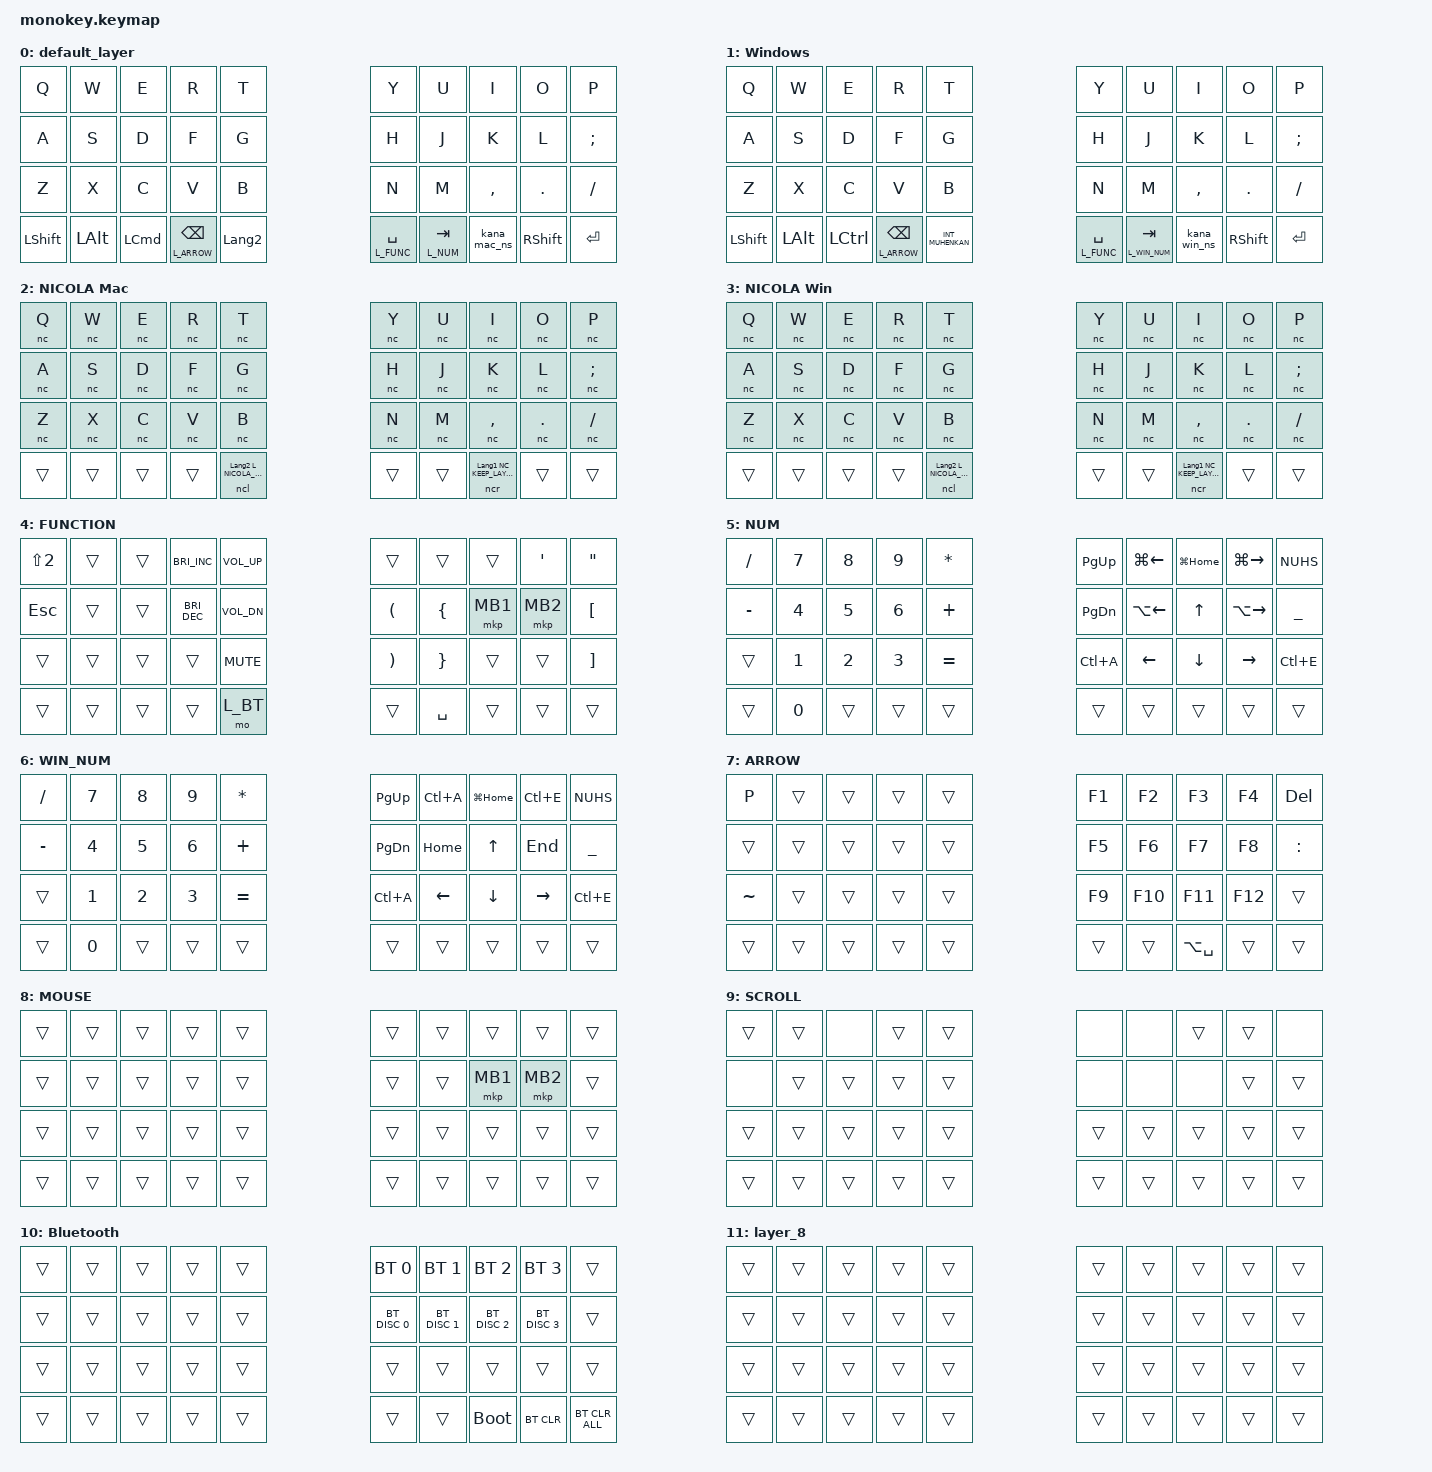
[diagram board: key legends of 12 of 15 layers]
#include <behaviors.dtsi>
#include <behaviors/nicola.dtsi>
#include <dt-bindings/zmk/bt.h>
#include <dt-bindings/zmk/keys.h>
#include <dt-bindings/zmk/pointing.h>

// レイヤー番号。NICOLA（親指シフト）レイヤーを基本レイヤーの直上に置き、FUNCTION 以降の
// ユーティリティレイヤーはその上に重なるようにする（NICOLA 中でも Space/Tab/Backspace の
// 長押しレイヤーが従来どおり使える）。番号を変えるときは monokey_R.overlay の
// zip_temp_layer / scroll-layers と monokey_R.conf の LAYER_n_COLOR も合わせる。
#define L_MAC        0
#define L_WIN        1
#define L_NICOLA_MAC 2
#define L_NICOLA_WIN 3
#define L_FUNC       4
#define L_NUM        5
#define L_WIN_NUM    6
#define L_ARROW      7
#define L_MOUSE      8
#define L_SCROLL     9
#define L_BT         10
#define L_SPARE_A    11
#define L_SPARE_B    12
#define L_SPARE_C    13
#define L_SPARE_D    14

// 文字キー同士の combo を NICOLA レイヤーでは無効にする（かなの高速ロールオーバーを
// combo が食わないようにする）。combo の layers に指定する。
#define NON_NICOLA_LAYERS L_MAC L_WIN L_FUNC L_NUM L_WIN_NUM L_ARROW L_MOUSE L_SCROLL L_BT L_SPARE_A L_SPARE_B L_SPARE_C L_SPARE_D
// Ctrl の combo は NICOLA レイヤーでも使う（Mac には Ctrl の物理キーがなく、入力中の
// Ctrl+K などに必要）。require-prior-idle-ms で直前の打鍵から間が空いたときだけ発火させ、
// かなの高速ロールオーバーを combo が食わないようにする。
#define ALL_LAYERS NON_NICOLA_LAYERS L_NICOLA_MAC L_NICOLA_WIN
#define CTRL_COMBO_IDLE_MS 150

// 親指シフト（NICOLA）の判定設定。Lacaille の使用感に合わせた初期値。
// - 判定方式: ms 方式（文字キーと親指キーの押下間隔が timeout-ms 以内なら同時打鍵）。
//   親指を先に押して遅れて文字を打った場合は窓に関係なくシフトがかかる。
// - 連続シフト: オン（親指を押し続けている間、後続の文字にもシフトがかかる）。
//   ただし親指がすでに文字をシフト済みのとき、次の文字キー押下から shift-release-ms 以内に
//   その親指が離されたら「離し遅れ」とみなして次の文字はシフトしない（「ょう」が「ょゔ」になる対策）。
// - 未確定ガード: かなを送出してから Enter/Esc を見るまでは、左親指単独タップの英数を抑止。
//   同じタップを guard-repeat-ms 以内に繰り返すと通す。
//   送ったかなの数を数え、Backspace/Delete で 1 ずつ減らして 0 になれば抑止を解除する
//   （変換中の最初の Backspace は取消扱い、修飾キー付きと guard-bs-hold-ms 以上の長押しは全消し扱い）。
//   最後のキー押下から guard-timeout-ms 無操作なら未確定文字は消えたとみなして抑止しない
//   （マウスでの確定やアプリ切替など、キーボードから見えない確定への備え）。
&nc {
    timeout-ms = <70>;
    continuous-shift = <1>;
    shift-release-ms = <50>;
    left-thumb = <LANGUAGE_2>;
    right-thumb = <LANGUAGE_1>;
    pending-guard = <1>;
    guard-repeat-ms = <1000>;
    guard-timeout-ms = <3000>;
    guard-bs-hold-ms = <500>;
};

&mt {
    flavor = "balanced";
    quick-tap-ms = <300>;
};

&lt { quick-tap-ms = <300>; };

/ {
    combos {
        compatible = "zmk,combos";

        scroll {
            layers = <NON_NICOLA_LAYERS>;
            bindings = <&mo L_SCROLL>;
            key-positions = <17 18>;
        };

        mb3 {
            layers = <NON_NICOLA_LAYERS>;
            bindings = <&mkp MB3>;
            key-positions = <19 18>;
        };

        right_ctrl {
            layers = <ALL_LAYERS>;
            require-prior-idle-ms = <CTRL_COMBO_IDLE_MS>;
            bindings = <&kp RCTRL>;
            key-positions = <28 29>;
        };

        left_ctrl {
            layers = <ALL_LAYERS>;
            require-prior-idle-ms = <CTRL_COMBO_IDLE_MS>;
            bindings = <&kp LCTRL>;
            key-positions = <20 21>;
        };

        changewin {
            layers = <NON_NICOLA_LAYERS>;
            timeout-ms = <50>;
            bindings = <&os_switch_hold L_WIN 0>;
            key-positions = <6 8>;
        };

        tomac {
            layers = <NON_NICOLA_LAYERS>;
            timeout-ms = <50>;
            bindings = <&os_switch_hold L_MAC 0>;
            key-positions = <7 8>;
        };

        lang1 {
            // NICOLA レイヤーでは位置37が右親指シフトなので除外する。
            // Shift が押されていても剥がして送る（Shift+かな は macOS でカタカナ固定）。
            layers = <NON_NICOLA_LAYERS>;
            bindings = <&lang1_ns>;
            key-positions = <36 37>;
        };

        lang2 {
            // LANG2 is IME Off on Windows; keep it out of thumb-shift chords.
            layers = <L_MAC>;
            bindings = <&kp LANGUAGE_2>;
            key-positions = <35 34>;
        };

        win {
            layers = <NON_NICOLA_LAYERS>;
            bindings = <&kp LEFT_GUI>;
            key-positions = <24 23>;
        };
    };

    behaviors {
        // かな (LANG1) を送るキーは、押されている Shift を剥がす。
        // macOS では Shift+かな がカタカナ固定モードへの切替なので、Shift の離し遅れや
        // 隣の右 Shift (位置38) との同時押しで偶発的にカタカナになるのを防ぐ。
        // mod-morph は両方の binding を同じにし、mods に Shift を指定すると Shift をマスクして送る。
        kana_mac_ns: kana_mac_ns {
            compatible = "zmk,behavior-mod-morph";
            #binding-cells = <0>;
            bindings = <&kana_mac>, <&kana_mac>;
            mods = <(MOD_LSFT|MOD_RSFT)>;
        };

        kana_win_ns: kana_win_ns {
            compatible = "zmk,behavior-mod-morph";
            #binding-cells = <0>;
            bindings = <&kana_win>, <&kana_win>;
            mods = <(MOD_LSFT|MOD_RSFT)>;
        };

        lang1_ns: lang1_ns {
            compatible = "zmk,behavior-mod-morph";
            #binding-cells = <0>;
            bindings = <&kp LANGUAGE_1>, <&kp LANGUAGE_1>;
            mods = <(MOD_LSFT|MOD_RSFT)>;
        };

        // Cancel on the first combo-key release; other keys must not force a hold.
        // A short combo is consumed without emitting text or changing layers.
        os_switch_hold: os_switch_hold {
            compatible = "zmk,behavior-hold-tap";
            #binding-cells = <2>;
            flavor = "tap-preferred";
            tapping-term-ms = <500>;
            quick-tap-ms = <0>;
            bindings = <&to>, <&none>;
        };

        right_click: right_click_behavior {
            compatible = "zmk,behavior-mouse-key";
            label = "RIGHT_CLICK";
            #binding-cells = <0>;

            // 右クリックは通常 MB2 に対応（ZMKの標準定義）

            bindings = <&mkp MB2>;
        };
    };

    macros {
        lang2_4: lang2_4 {
            compatible = "zmk,behavior-macro";
            #binding-cells = <0>;
            wait-ms = <30>;
            tap-ms = <30>;
            bindings = <&kp LANGUAGE_2 &kp NUMBER_4>;
        };

        lang2_5: lang2_5 {
            compatible = "zmk,behavior-macro";
            #binding-cells = <0>;
            wait-ms = <30>;
            tap-ms = <30>;
            bindings =
                <&macro_wait_time 100>,
                <&macro_press>,
                <&kp LANG2>,
                <&macro_tap>,
                <&kp N5>,
                <&macro_release>,
                <&kp LANG2>;
        };

        // かなキー（位置37）: IME をかなにしてから NICOLA レイヤーへ入る。
        // 戻るときは NICOLA レイヤー内の左親指（英数）単独タップが LANG2 を送ってレイヤーを抜ける。
        kana_mac: kana_mac {
            compatible = "zmk,behavior-macro";
            #binding-cells = <0>;
            wait-ms = <10>;
            tap-ms = <10>;
            bindings = <&kp LANGUAGE_1 &tog L_NICOLA_MAC>;
        };

        kana_win: kana_win {
            compatible = "zmk,behavior-macro";
            #binding-cells = <0>;
            wait-ms = <10>;
            tap-ms = <10>;
            bindings = <&kp LANGUAGE_1 &tog L_NICOLA_WIN>;
        };
    };

    keymap {
        compatible = "zmk,keymap";

        default_layer {
            bindings = <
&kp Q           &kp W         &kp E             &kp R                  &kp T                                               &kp Y           &kp U  &kp I      &kp O            &kp P
&kp A           &kp S         &kp D             &kp F                  &kp G                                               &kp H           &kp J  &kp K      &kp L            &kp SEMICOLON
&kp Z           &kp X         &kp C             &kp V                  &kp B                                               &kp N           &kp M  &kp COMMA  &kp PERIOD       &kp SLASH
&kp LEFT_SHIFT  &kp LEFT_ALT  &kp LEFT_COMMAND  &lt L_ARROW BACKSPACE  &kp LANGUAGE_2  &lt L_FUNC SPACE  &lt L_NUM TAB     &kana_mac_ns                      &kp RIGHT_SHIFT  &kp RET
            >;

            sensor-bindings = <&inc_dec_kp PG_UP PAGE_DOWN>;
        };

        Windows {
            bindings = <
&kp Q      &kp W         &kp E             &kp R                  &kp T                                                     &kp Y           &kp U  &kp I      &kp O       &kp P
&kp A      &kp S         &kp D             &kp F                  &kp G                                                     &kp H           &kp J  &kp K      &kp L       &kp SEMICOLON
&kp Z      &kp X         &kp C             &kp V                  &kp B                                                     &kp N           &kp M  &kp COMMA  &kp PERIOD  &kp SLASH
&kp LSHFT  &kp LEFT_ALT  &kp LEFT_CONTROL  &lt L_ARROW BACKSPACE  &kp INT_MUHENKAN  &lt L_FUNC SPACE  &lt L_WIN_NUM TAB     &kana_win_ns                      &kp RSHIFT  &kp RET
            >;

            sensor-bindings = <&inc_dec_kp PG_UP PAGE_DOWN>;
        };

        // 親指シフト（NICOLA）。文字キーは &nc、親指キーは &ncl / &ncr。
        // 左親指（位置34）単独タップ = 英数(LANG2) を送ってこのレイヤーを抜ける。
        // 右親指（位置37）単独タップ = かな(LANG1) を送る（レイヤーは維持）。
        // それ以外のキーは &trans で下のレイヤー（Space/Tab/Backspace の長押しなど）に落とす。
        nicola_mac {
            display-name = "NICOLA Mac";
            bindings = <
&nc Q   &nc W   &nc E   &nc R   &nc T                                                   &nc Y   &nc U   &nc I      &nc O    &nc P
&nc A   &nc S   &nc D   &nc F   &nc G                                                   &nc H   &nc J   &nc K      &nc L    &nc SEMI
&nc Z   &nc X   &nc C   &nc V   &nc B                                                   &nc N   &nc M   &nc COMMA  &nc DOT  &nc SLASH
&trans  &trans  &trans  &trans  &ncl LANGUAGE_2 L_NICOLA_MAC  &trans  &trans            &ncr LANGUAGE_1 NC_KEEP_LAYER       &trans   &trans
            >;
        };

        nicola_win {
            display-name = "NICOLA Win";
            bindings = <
&nc Q   &nc W   &nc E   &nc R   &nc T                                                   &nc Y   &nc U   &nc I      &nc O    &nc P
&nc A   &nc S   &nc D   &nc F   &nc G                                                   &nc H   &nc J   &nc K      &nc L    &nc SEMI
&nc Z   &nc X   &nc C   &nc V   &nc B                                                   &nc N   &nc M   &nc COMMA  &nc DOT  &nc SLASH
&trans  &trans  &trans  &trans  &ncl LANGUAGE_2 L_NICOLA_WIN  &trans  &trans            &ncr LANGUAGE_1 NC_KEEP_LAYER       &trans   &trans
            >;
        };

        FUNCTION {
            bindings = <
&kp LS(NUMBER_2)  &trans  &trans  &kp C_BRI_INC  &kp C_VOL_UP                        &trans                 &trans           &trans    &kp SINGLE_QUOTE  &kp DOUBLE_QUOTES
&kp ESC           &trans  &trans  &kp C_BRI_DEC  &kp C_VOL_DN                        &kp LEFT_PARENTHESIS   &kp LEFT_BRACE   &mkp MB1  &mkp MB2          &kp LEFT_BRACKET
&trans            &trans  &trans  &trans         &kp C_MUTE                          &kp RIGHT_PARENTHESIS  &kp RIGHT_BRACE  &trans    &trans            &kp RIGHT_BRACKET
&trans            &trans  &trans  &trans         &mo L_BT      &trans  &kp SPACE     &trans                                            &trans            &trans
            >;
        };

        NUM {
            bindings = <
&kp SLASH  &kp NUMBER_7  &kp NUMBER_8  &kp NUMBER_9  &kp STAR                   &kp PAGE_UP    &kp LG(LEFT)    &kp LG(HOME)    &kp LG(RIGHT)    &kp NUHS
&kp MINUS  &kp NUMBER_4  &kp NUMBER_5  &kp NUMBER_6  &kp PLUS                   &kp PAGE_DOWN  &kp LA(LEFT)    &kp UP_ARROW    &kp LA(RIGHT)    &kp UNDERSCORE
&trans     &kp NUMBER_1  &kp NUMBER_2  &kp NUMBER_3  &kp EQUAL                  &kp LC(A)      &kp LEFT_ARROW  &kp DOWN_ARROW  &kp RIGHT_ARROW  &kp LC(E)
&trans     &kp NUMBER_0  &trans        &trans        &trans     &trans  &trans  &trans                                         &trans           &trans
            >;
        };

        WIN_NUM {
            bindings = <
&kp SLASH  &kp NUMBER_7  &kp NUMBER_8  &kp NUMBER_9  &kp STAR                   &kp PAGE_UP    &kp LC(A)       &kp LG(HOME)    &kp LC(E)        &kp NUHS
&kp MINUS  &kp NUMBER_4  &kp NUMBER_5  &kp NUMBER_6  &kp PLUS                   &kp PAGE_DOWN  &kp HOME        &kp UP_ARROW    &kp END          &kp UNDERSCORE
&trans     &kp NUMBER_1  &kp NUMBER_2  &kp NUMBER_3  &kp EQUAL                  &kp LC(A)      &kp LEFT_ARROW  &kp DOWN_ARROW  &kp RIGHT_ARROW  &kp LC(E)
&trans     &kp NUMBER_0  &trans        &trans        &trans     &trans  &trans  &trans                                         &trans           &trans
            >;
        };

        ARROW {
            bindings = <
&kp P      &trans  &trans  &trans  &trans                  &kp F1         &kp F2   &kp F3   &kp F4   &kp DELETE
&trans     &trans  &trans  &trans  &trans                  &kp F5         &kp F6   &kp F7   &kp F8   &kp COLON
&kp TILDE  &trans  &trans  &trans  &trans                  &kp F9         &kp F10  &kp F11  &kp F12  &trans
&trans     &trans  &trans  &trans  &trans  &trans  &trans  &kp LA(SPACE)                    &trans   &trans
            >;

            sensor-bindings = <&inc_dec_kp LC(PAGE_UP) LC(PAGE_DOWN)>;
        };

        MOUSE {
            bindings = <
&trans  &trans  &trans  &trans  &trans                  &trans  &trans  &trans    &trans    &trans
&trans  &trans  &trans  &trans  &trans                  &trans  &trans  &mkp MB1  &mkp MB2  &trans
&trans  &trans  &trans  &trans  &trans                  &trans  &trans  &trans    &trans    &trans
&trans  &trans  &trans  &trans  &trans  &trans  &trans  &trans                    &trans    &trans
            >;
        };

        SCROLL {
            bindings = <
&trans  &trans  &none   &trans  &trans                  &none   &none   &trans  &trans  &none
&none   &trans  &trans  &trans  &trans                  &none   &none   &none   &trans  &trans
&trans  &trans  &trans  &trans  &trans                  &trans  &trans  &trans  &trans  &trans
&trans  &trans  &trans  &trans  &trans  &trans  &trans  &trans                  &trans  &trans
            >;
        };

        Bluetooth {
            bindings = <
&trans  &trans  &trans  &trans  &trans                  &bt BT_SEL 0   &bt BT_SEL 1   &bt BT_SEL 2   &bt BT_SEL 3   &trans
&trans  &trans  &trans  &trans  &trans                  &bt BT_DISC 0  &bt BT_DISC 1  &bt BT_DISC 2  &bt BT_DISC 3  &trans
&trans  &trans  &trans  &trans  &trans                  &trans         &trans         &trans         &trans         &trans
&trans  &trans  &trans  &trans  &trans  &trans  &trans  &bootloader                                  &bt BT_CLR     &bt BT_CLR_ALL
            >;
        };

        layer_8 {
            bindings = <
&trans  &trans  &trans  &trans  &trans                  &trans  &trans  &trans  &trans  &trans
&trans  &trans  &trans  &trans  &trans                  &trans  &trans  &trans  &trans  &trans
&trans  &trans  &trans  &trans  &trans                  &trans  &trans  &trans  &trans  &trans
&trans  &trans  &trans  &trans  &trans  &trans  &trans  &trans                  &trans  &trans
            >;
        };

        layer_9 {
            bindings = <
&trans  &trans  &trans  &trans  &trans                  &trans  &trans  &trans  &trans  &trans
&trans  &trans  &trans  &trans  &trans                  &trans  &trans  &trans  &trans  &trans
&trans  &trans  &trans  &trans  &trans                  &trans  &trans  &trans  &trans  &trans
&trans  &trans  &trans  &trans  &trans  &trans  &trans  &trans                  &trans  &trans
            >;
        };

        layer_10 {
            bindings = <
&trans  &trans  &trans  &trans  &trans                  &trans  &trans  &trans  &trans  &trans
&trans  &trans  &trans  &trans  &trans                  &trans  &trans  &trans  &trans  &trans
&trans  &trans  &trans  &trans  &trans                  &trans  &trans  &trans  &trans  &trans
&trans  &trans  &trans  &trans  &trans  &trans  &trans  &trans                  &trans  &trans
            >;
        };

        layer_11 {
            bindings = <
&trans  &trans  &trans  &trans  &trans                  &trans  &trans  &trans  &trans  &trans
&trans  &trans  &trans  &trans  &trans                  &trans  &trans  &trans  &trans  &trans
&trans  &trans  &trans  &trans  &trans                  &trans  &trans  &trans  &trans  &trans
&trans  &trans  &trans  &trans  &trans  &trans  &trans  &trans                  &trans  &trans
            >;
        };
    };
};
